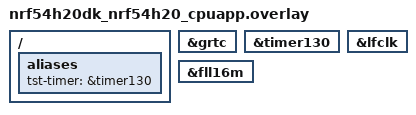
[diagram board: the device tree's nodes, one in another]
/* SPDX-License-Identifier: LicenseRef-Nordic-5-Clause */

/ {
	aliases {
		tst-timer = &timer130;
	};
};

&grtc {
	/delete-property/ child-owned-channels;
};

&timer130 {
	status = "okay";
};

&fll16m {
	status = "okay";
};

&lfclk {
	status = "okay";
};
